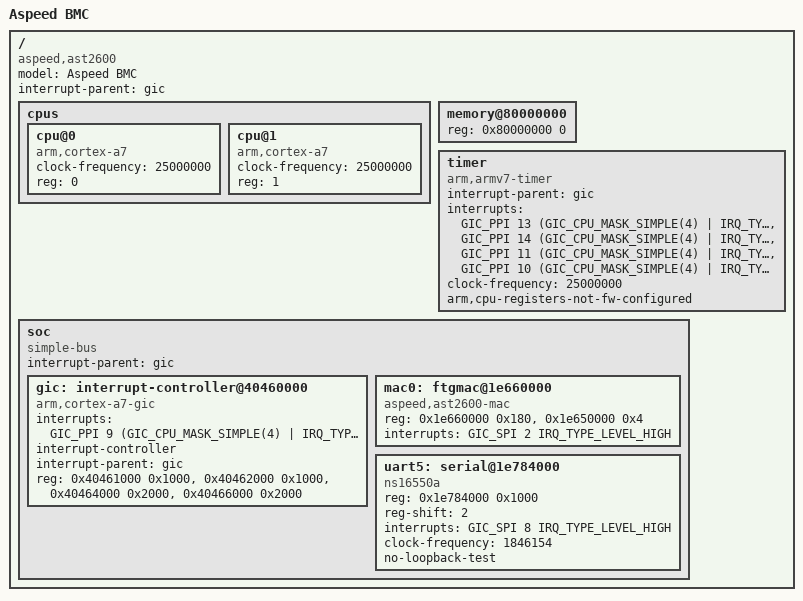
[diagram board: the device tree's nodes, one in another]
// SPDX-License-Identifier: GPL-2.0+
// Copyright 2019 ASPEED Technology Inc.
// Copyright 2019 IBM Corp.

#include <dt-bindings/interrupt-controller/arm-gic.h>
#include <dt-bindings/clock/aspeed-clock.h>
#include <dt-bindings/gpio/gpio.h>

/ {
	model = "Aspeed BMC";
	compatible = "aspeed,ast2600";
	#address-cells = <1>;
	#size-cells = <1>;
	interrupt-parent = <&gic>;

	cpus {
		#address-cells = <1>;
		#size-cells = <0>;

		cpu@0 {
			compatible = "arm,cortex-a7";
			device_type = "cpu";
			clock-frequency = <25000000>;
			reg = <0>;
		};

		cpu@1 {
			compatible = "arm,cortex-a7";
			device_type = "cpu";
			clock-frequency = <25000000>;
			reg = <1>;
		};
	};

	memory@80000000 {
		reg = <0x80000000 0>;
	};

	timer {
		compatible = "arm,armv7-timer";
		interrupt-parent = <&gic>;
		interrupts = <GIC_PPI 13 (GIC_CPU_MASK_SIMPLE(4) | IRQ_TYPE_LEVEL_LOW)>,
				<GIC_PPI 14 (GIC_CPU_MASK_SIMPLE(4) | IRQ_TYPE_LEVEL_LOW)>,
				<GIC_PPI 11 (GIC_CPU_MASK_SIMPLE(4) | IRQ_TYPE_LEVEL_LOW)>,
				<GIC_PPI 10 (GIC_CPU_MASK_SIMPLE(4) | IRQ_TYPE_LEVEL_LOW)>;
				clock-frequency = <25000000>;
		arm,cpu-registers-not-fw-configured;
	};

	soc {
		compatible = "simple-bus";
		#address-cells = <1>;
		#size-cells = <1>;
		device_type = "soc";
		interrupt-parent = <&gic>;
		ranges;

		gic: interrupt-controller@40460000 {
			compatible = "arm,cortex-a7-gic";
			interrupts = <GIC_PPI 9 (GIC_CPU_MASK_SIMPLE(4) | IRQ_TYPE_LEVEL_HIGH)>;
			#interrupt-cells = <3>;
			interrupt-controller;
			interrupt-parent = <&gic>;
			reg = <0x40461000 0x1000>,
			    <0x40462000 0x1000>,
			    <0x40464000 0x2000>,
			    <0x40466000 0x2000>;
		};

		mac0: ftgmac@1e660000 {
			compatible = "aspeed,ast2600-mac", "faraday,ftgmac100";
			reg = <0x1e660000 0x180>, <0x1e650000 0x4>;
			#address-cells = <1>;
			#size-cells = <0>;
			interrupts = <GIC_SPI 2 IRQ_TYPE_LEVEL_HIGH>;
//			phy-handle = <&phy0>;
		};

		uart5: serial@1e784000 {
			compatible = "ns16550a";
			reg = <0x1e784000 0x1000>;
			reg-shift = <2>;
			interrupts = <GIC_SPI 8 IRQ_TYPE_LEVEL_HIGH>;
			clock-frequency = <1846154>;
			no-loopback-test;
		};
	};
};
